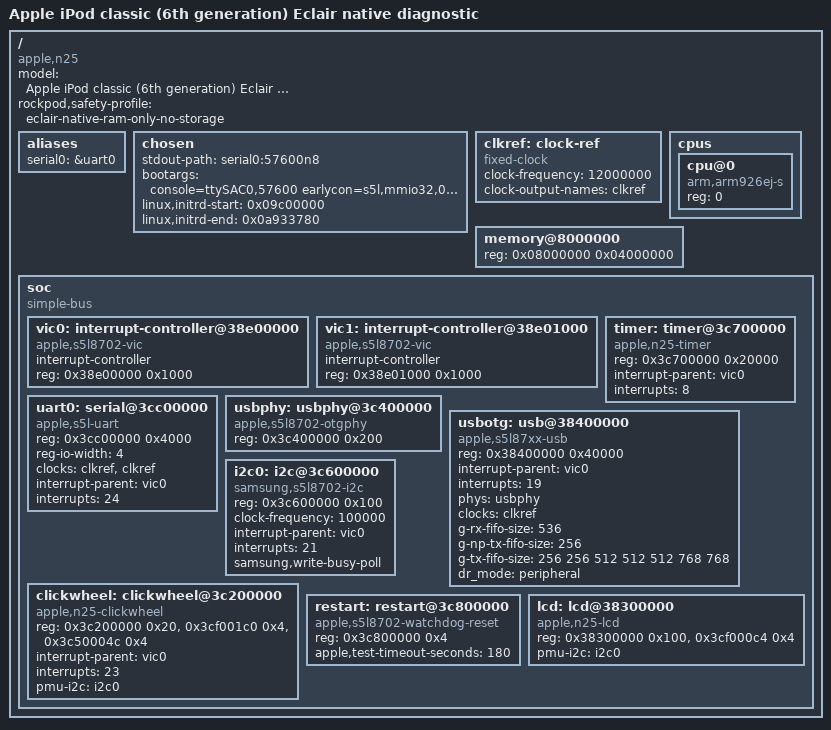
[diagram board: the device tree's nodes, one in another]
// SPDX-License-Identifier: GPL-2.0+
/*
 * Apple iPod classic (6th generation), N25.
 * Eclair native profile: Binder, RAM-backed mutable state, and no storage bus.
 */

/dts-v1/;

/ {
	#address-cells = <1>;
	#size-cells = <1>;
	model = "Apple iPod classic (6th generation) Eclair native diagnostic";
	compatible = "apple,n25", "samsung,s5l8702";
	rockpod,safety-profile = "eclair-native-ram-only-no-storage";

	aliases {
		serial0 = &uart0;
	};

	chosen {
		stdout-path = "serial0:57600n8";
		bootargs = "console=ttySAC0,57600 earlycon=s5l,mmio32,0x3cc00000 rdinit=/init androidboot.hardware=n25 androidboot.console=ttySAC0 loglevel=8 panic=5";
		/*
		 * Fixed RAM-only handoff used by the Rockbox Select+Right boot path.
		 * U-Boot normally adds these properties to the FIT's DTB; keeping
		 * them in the DTB also makes the independently checksummed direct
		 * boot components self-contained.
		 */
		linux,initrd-start = <0x09c00000>;
		linux,initrd-end = <0x0a933780>;
	};

	clkref: clock-ref {
		compatible = "fixed-clock";
		#clock-cells = <0>;
		clock-frequency = <12000000>;
		clock-output-names = "clkref";
	};

	cpus {
		#address-cells = <1>;
		#size-cells = <0>;

		cpu@0 {
			device_type = "cpu";
			compatible = "arm,arm926ej-s";
			reg = <0>;
		};
	};

	memory@8000000 {
		device_type = "memory";
		reg = <0x08000000 0x04000000>;
	};

	soc {
		compatible = "simple-bus";
		#address-cells = <1>;
		#size-cells = <1>;
		ranges;

		vic0: interrupt-controller@38e00000 {
			compatible = "apple,s5l8702-vic";
			interrupt-controller;
			reg = <0x38e00000 0x1000>;
			#interrupt-cells = <1>;
		};

		vic1: interrupt-controller@38e01000 {
			compatible = "apple,s5l8702-vic";
			interrupt-controller;
			reg = <0x38e01000 0x1000>;
			#interrupt-cells = <1>;
		};

		timer: timer@3c700000 {
			compatible = "apple,n25-timer", "samsung,s5l8702-timer";
			reg = <0x3c700000 0x20000>;
			interrupt-parent = <&vic0>;
			interrupts = <8>;
		};

		uart0: serial@3cc00000 {
			compatible = "apple,s5l-uart";
			reg = <0x3cc00000 0x4000>;
			reg-io-width = <4>;
			clocks = <&clkref>, <&clkref>;
			clock-names = "uart", "clk_uart_baud0";
			interrupt-parent = <&vic0>;
			interrupts = <24>;
			status = "okay";
		};

		usbphy: usbphy@3c400000 {
			compatible = "apple,s5l8702-otgphy";
			reg = <0x3c400000 0x200>;
			status = "okay";
			#phy-cells = <0>;
		};

		usbotg: usb@38400000 {
			compatible = "apple,s5l87xx-usb";
			reg = <0x38400000 0x40000>;
			interrupt-parent = <&vic0>;
			interrupts = <19>;
			phys = <&usbphy>;
			phy-names = "usb2-phy";
			clocks = <&clkref>;
			clock-names = "otg";
			g-rx-fifo-size = <536>;
			g-np-tx-fifo-size = <256>;
			g-tx-fifo-size = <256 256 512 512 512 768 768>;
			dr_mode = "peripheral";
			status = "okay";
		};

		/*
		 * Narrow display/Hold-control bus only.  There are deliberately no DT child
		 * devices, so Linux cannot bind the generic PMU, regulator, charger,
		 * EEPROM, or storage drivers.  The LCD driver has a six-register
		 * PCF50635 display-power allowlist copied from Rockbox; the click-wheel
		 * driver may additionally read only GPIOSTAT for Hold.
		 */
		i2c0: i2c@3c600000 {
			compatible = "samsung,s5l8702-i2c";
			reg = <0x3c600000 0x100>;
			clock-frequency = <100000>;
			interrupt-parent = <&vic0>;
			interrupts = <21>;
			samsung,write-busy-poll;
			status = "okay";
		};

		/*
		 * Rockbox-derived Classic click wheel.  The extra four-byte ranges
		 * expose only PCON14 and click-wheel clock gate 33.  Hold is the
		 * read-only PCF50635 GPIOSTAT GPIO2 bit on the display-control bus.
		 */
		clickwheel: clickwheel@3c200000 {
			compatible = "apple,n25-clickwheel";
			reg = <0x3c200000 0x20>, <0x3cf001c0 0x4>,
			      <0x3c50004c 0x4>;
			reg-names = "wheel", "pcon14", "pwrcon1";
			interrupt-parent = <&vic0>;
			interrupts = <23>;
			pmu-i2c = <&i2c0>;
			status = "okay";
		};

		/*
		 * Reset-only watchdog mapping.  The mandatory three-minute volatile
		 * test window returns control to the installed boot path even if
		 * Android userspace is unresponsive.
		 */
		restart: restart@3c800000 {
			compatible = "apple,s5l8702-watchdog-reset";
			reg = <0x3c800000 0x4>;
			apple,test-timeout-seconds = <180>;
			status = "okay";
		};

		/*
		 * Storage-independent display.  The second range is the read-only
		 * PDAT6 panel-type strap used by Rockbox.  Panel initialization and
		 * the narrowly allowlisted PCF50635 display-power writes fail closed.
		 */
		lcd: lcd@38300000 {
			compatible = "apple,n25-lcd";
			reg = <0x38300000 0x100>, <0x3cf000c4 0x4>;
			reg-names = "lcd", "panel-strap";
			pmu-i2c = <&i2c0>;
			status = "okay";
		};
	};
};

/* No ATA, CE-ATA, MMC, NAND, NOR, SPI, EEPROM, or filesystem node is allowed. */
